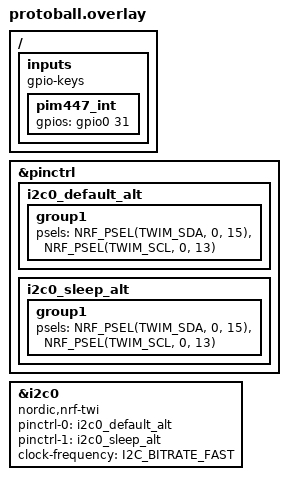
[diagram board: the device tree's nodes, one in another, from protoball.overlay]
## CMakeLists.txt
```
cmake_minimum_required(VERSION 3.20.0)
set(BOARD nrf52840dongle_nrf52840)
set(DTC_OVERLAY_FILE protoball.overlay)

find_package(Zephyr)
project(protoball)

include_directories(src)
target_sources(app PRIVATE src/main.c src/leds.c src/pim.c src/hid.c)

set_property(GLOBAL APPEND PROPERTY HEX_FILES_TO_MERGE
	${app_bootloader_hex}
	${PROJECT_BINARY_DIR}/${KERNEL_HEX_NAME}
	${app_provision_hex})
```

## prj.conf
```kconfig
CONFIG_I2C=y
CONFIG_GPIO=y
CONFIG_PWM=y
CONFIG_LOG=y
CONFIG_SERIAL=y
CONFIG_CONSOLE=y
CONFIG_HEAP_MEM_POOL_SIZE=256

CONFIG_USB_DEVICE_STACK=y
CONFIG_USB_DEVICE_HID=y
CONFIG_USB_DEVICE_PRODUCT="ProtoBall HID"
CONFIG_USB_DEVICE_PID=0x0007
CONFIG_USB_DEVICE_INITIALIZE_AT_BOOT=n
```

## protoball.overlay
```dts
/ {
	inputs {
		compatible = "gpio-keys";
		status = "okay";
		
		pim447_int: pim447_int {
			gpios = <&gpio0 31 (GPIO_ACTIVE_HIGH)>;	
		};
	};
};

&pinctrl {
	i2c0_default_alt: i2c0_default_alt {
		group1 {
			psels = <NRF_PSEL(TWIM_SDA, 0, 15)>,
				<NRF_PSEL(TWIM_SCL, 0, 13)>;
		};
	};
	i2c0_sleep_alt: i2c0_sleep_alt {
		group1 {
			psels = <NRF_PSEL(TWIM_SDA, 0, 15)>,
				<NRF_PSEL(TWIM_SCL, 0, 13)>;
		};
	};
};

&i2c0 {
	compatible = "nordic,nrf-twi";
	status = "okay";
	pinctrl-0 = <&i2c0_default_alt>;
	pinctrl-1 = <&i2c0_sleep_alt>;
	pinctrl-names = "default", "sleep";
	clock-frequency = <I2C_BITRATE_FAST>;
};
```

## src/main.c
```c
#include <stdint.h>
#include <leds.h>
#include <pim.h>
#include <hid.h>
#include <zephyr/devicetree.h>
#include <zephyr/kernel.h>
#include <zephyr/drivers/i2c.h>
#include <zephyr/drivers/gpio.h>
#include <zephyr/logging/log.h>

#define MS_REPORT 8

LOG_MODULE_REGISTER(main);

uint8_t scaler = 5;

void set_color(uint8_t r, uint8_t g, uint8_t b, uint8_t w) {
	set_led_color(r,g,b);
	pim_set_color(r,g,b,w);
} 

void on_tb_move(uint8_t left, uint8_t right, uint8_t up, uint8_t down, uint8_t button) {
	//LOG_INF("left: %i, right: %i, up: %i, down: %i, button: %i", left, right, up, down, button);
	int8_t x = (right - left) * scaler;
	int8_t y = (down - up) * scaler;
	uint8_t b = button ? LEFT_MOUSE_BTN : 0;
	hid_add_to_report(b,x,y);
}

void main() {
	config_leds();
	if (!config_pim()) return;
	if (!config_hid()) return;
	pim_set_callback(on_tb_move);
	LOG_INF("Success!");

	set_color(255, 255, 255, 0);
	uint32_t last_report = 0;
	while (1) {
		k_msleep(1);
		poll_pim();
		if (last_report + MS_REPORT < k_uptime_get()) {
			hid_report();
			last_report = k_uptime_get();
		}
	}
}
```

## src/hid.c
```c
#include <stdint.h>
#include <hid.h>
#include <zephyr/kernel.h>
#include <zephyr/device.h>
#include <zephyr/usb/usb_device.h>
#include <zephyr/usb/class/usb_hid.h>
#include <zephyr/logging/log.h>

LOG_MODULE_REGISTER(hid);

const struct device *hid_dev;

static const uint8_t hid_report_descriptor[] = HID_MOUSE_REPORT_DESC(2);

#define BTN_REP_POS 0
#define X_REP_POS 1
#define Y_REP_POS 2

static uint8_t rep_status[4];
static enum usb_dc_status_code usb_status;

static void usb_status_callback(enum usb_dc_status_code sc, const uint8_t *param) {
	usb_status = sc;
}

uint8_t config_hid() {
	hid_dev = device_get_binding("HID_0");
	if (hid_dev == NULL) {
		LOG_ERR("Cannot get USB HID Device");
		return 0;
	}

	usb_hid_register_device(hid_dev, hid_report_descriptor, sizeof(hid_report_descriptor), NULL);
	usb_hid_init(hid_dev);
	if (usb_enable(usb_status_callback)) {
		LOG_ERR("Failed to enable USB");
		return 0;
	}
	return 1;
}

static uint8_t report = 0;
void hid_add_to_report(uint8_t btns, int8_t x, int8_t y) {
	rep_status[X_REP_POS] = (uint8_t) ((int8_t)rep_status[X_REP_POS] + x);
	rep_status[Y_REP_POS] = (uint8_t) ((int8_t)rep_status[Y_REP_POS] + y);
	rep_status[BTN_REP_POS] = btns;
	report = 1;
}

uint8_t hid_report() {
	if (!report) return 1;

	int ret = hid_int_ep_write(hid_dev, rep_status, sizeof(rep_status), NULL);
	if (ret) {
		LOG_ERR("write error, %d", ret);
		return 0;
	}
	report = 0;
	rep_status[BTN_REP_POS] = 0;
	rep_status[X_REP_POS] = 0;
	rep_status[Y_REP_POS] = 0;
	return 1;
}
```

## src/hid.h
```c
#ifndef PROTOBALL_HID_H
#define PROTOBALL_HID_H

#define LEFT_MOUSE_BTN BIT(0)
#define CENTER_MOUSE_BTN BIT(2)
#define RIGHT_MOUSE_BTN BIT(1)

uint8_t config_hid();

void hid_add_to_report(uint8_t btns, int8_t x, int8_t y);

uint8_t hid_report();

#endif /* PROTOBALL_HID_H */
```

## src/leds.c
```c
#include <stdint.h>
#include <leds.h>
#include <zephyr/devicetree.h>
#include <zephyr/drivers/pwm.h>
#include <zephyr/logging/log.h>

#define NLEDS 3

static const struct pwm_dt_spec rgb_led[NLEDS] = {
	PWM_DT_SPEC_GET(DT_NODELABEL(red_pwm_led)),
	PWM_DT_SPEC_GET(DT_NODELABEL(green_pwm_led)),
	PWM_DT_SPEC_GET(DT_NODELABEL(blue_pwm_led))
};

LOG_MODULE_REGISTER(leds);

static uint32_t max_period;
static uint32_t period_mult;
static uint32_t rgb_ps[NLEDS];

void config_leds() {
	for (int i = 0; i<NLEDS; i++) if (!device_is_ready(rgb_led[i].dev)) LOG_ERR("PWM rgb_led[%i] not ready", i);
	max_period = rgb_led[0].period;
	period_mult = max_period/255;
	set_led_color(0,0,0);
}

void set_led_color(uint8_t r, uint8_t g, uint8_t b) {
	rgb_ps[0] = r * period_mult;
	rgb_ps[1] = g * period_mult;
	rgb_ps[2] = b * period_mult;

	for (int i = 0; i < NLEDS; i++) {
		pwm_set_pulse_dt(&rgb_led[i], rgb_ps[i]);
	}
}
```

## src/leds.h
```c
#ifndef PROTOBALL_LEDS_H
#define PROTOBALL_LEDS_H

void config_leds();

void set_led_color(uint8_t r, uint8_t g, uint8_t b);

#endif /* PROTOBALL_LEDS_H */
```

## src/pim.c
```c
#include <stdint.h>
#include <pim.h>
#include <zephyr/devicetree.h>
#include <zephyr/kernel.h>
#include <zephyr/drivers/gpio.h>
#include <zephyr/drivers/i2c.h>
#include <zephyr/logging/log.h>

static const uint16_t pim_addr = 0x0A;
static const uint8_t pim_led_reg = 0x00;
static const uint8_t pim_mov_reg = 0x04;
static const uint8_t pim_int_reg = 0xF9;

#define PIM_BTN_MSK 	0x80
#define PIM_INT_EN_MSK 	0x02

LOG_MODULE_REGISTER(PIM);

static const struct gpio_dt_spec pim_int = GPIO_DT_SPEC_GET(DT_NODELABEL(pim447_int), gpios);
static const struct device *i2c = DEVICE_DT_GET(DT_NODELABEL(i2c0));

uint8_t config_pim() {
	gpio_pin_configure_dt(&pim_int, GPIO_INPUT);

	if (i2c == NULL || !device_is_ready(i2c)) {
		LOG_ERR("i2c device setup failed!");
		return 0;
	}
	//enable interrupt pin
	if (i2c_reg_update_byte(i2c, pim_addr, pim_int_reg, PIM_INT_EN_MSK, PIM_INT_EN_MSK)) {
		LOG_ERR("i2c failed to enable interrupt pin");
	}
	return 1;
}

static void (*move_callback)(uint8_t l, uint8_t r, uint8_t u, uint8_t d, uint8_t s) = NULL;
void pim_set_callback(void (*cb)(uint8_t l, uint8_t r, uint8_t u, uint8_t d, uint8_t s)) {
	move_callback = cb;
}

static uint8_t color[4] = {0U, 0U, 0U, 0U};
void pim_set_color(uint8_t r, uint8_t g, uint8_t b, uint8_t w) {
	color[0] = r;
	color[1] = g;
	color[2] = b;
	color[3] = w;
	if (i2c_burst_write(i2c, pim_addr, pim_led_reg, color, 4)) {
		LOG_ERR("i2c write color failed!");
	}
}

uint8_t move_buf[5] = {0U, 0U, 0U, 0U, 0U};
void poll_pim() {
	if (!gpio_pin_get_dt(&pim_int)) {
		if (i2c_burst_read(i2c, pim_addr, pim_mov_reg, move_buf, 5)) {
			LOG_ERR("i2c read move reg failed!");
			return;
		}
		if (move_callback != NULL) {
			move_callback(move_buf[0], move_buf[1], move_buf[2], move_buf[3], move_buf[4] & PIM_BTN_MSK);
		}
	}
}
```

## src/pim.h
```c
#ifndef PROTOBALL_PIM_H
#define PROTOBALL_PIM_H

uint8_t config_pim();

void pim_set_callback(void (*cb)(uint8_t l, uint8_t r, uint8_t u, uint8_t d, uint8_t s));

void pim_set_color(uint8_t r, uint8_t g, uint8_t b, uint8_t w);

void poll_pim();

#endif /* PROTOBALL_PIM_H */
```
